# BlueNRG2 register map
Vendor: STMicroelectronics; Series: BlueNRG1; File version: 1.0.0
ARM 32-bit Cortex-M0 Microcontroller based device, CPU clock up to 32MHz
CPU: CM0 r0p0, little endian, no MPU, no FPU, 2 interrupt priority bits
Registers are 32-bit, read-write, reset 0x0 unless marked. A register's access mark holds for its fields unless they carry their own. Offsets are from the block's base; lines under a group give offsets from that group; [hi:lo] are bit positions; {n}, {i} and the like mark numbered series; 'fields as' and 'values as' point back to an identical list; <NAME> marks a mode.

## Memory map
0x40000000 GPIO size 0x1000 — GPIO Controller
0x40100000 FLASH size 0x1000 — Flash Controller
0x40200000 SYSTEM_CTRL size 0x1000 — System controller
0x40300000 UART size 0x1000
0x40400000 SPI size 0x1000 — Serial peripheral interface
0x40700000 WDG size 0x1000 — Watchdog
0x40800000 ADC size 0x1000
0x40900000 CKGEN_SOC size 0x1000 — Clock Gen SOC
0x40A00000 I2C2 size 0x1000
0x40B00000 I2C1 size 0x1000
0x40C00000 AHBUPCONV size 0x1000 — AHB up/down converter converter
0x40D00000 MFT1 size 0x1000
0x40E00000 MFT2 size 0x1000
0x40F00000 RTC size 0x1000 — Real-Time Counter
0x48000000 BLUE_CTRL size 0x1000 — BLUE Controller
0x48100000 CKGEN_BLE size 0x1000 — Clock Gen BLE
0xA0000000 DMA size 0x1000
0xA0000008 DMA_CH0 size 0x1000 — DMA channel
0xA000001C DMA_CH1 size 0x1000
0xA0000030 DMA_CH2 size 0x1000
0xA0000044 DMA_CH3 size 0x1000
0xA0000058 DMA_CH4 size 0x1000
0xA000006C DMA_CH5 size 0x1000
0xA0000080 DMA_CH6 size 0x1000
0xA0000094 DMA_CH7 size 0x1000
0xB0000000 RNG size 0x1000
0xC0000000 PKA size 0x1000

## Interrupts
0 GPIO — GPIO bus interrupt
1 NVM (FLASH) — Non-volatile memory (Flash) controller interrupt
4 UART — UART interrupt
5 SPI — SPI interrupt
6 BLUE_CTRL — BLUE controller interrupt
7 WDG — Watchdog interrupt
13 ADC — ADC interrupt
14 I2C2 — I2C 2 interrupt
15 I2C1 — I2C 1 interrupt
17 MFT1A (MFT1) — Multi functional timer MFT1 interrupt A
18 MFT1B (MFT1) — Multi functional timer MFT1 interrupt B
19 MFT2A (MFT2) — Multi functional timer MFT2 interrupt A
20 MFT2B (MFT2) — Multi functional timer MFT2 interrupt B
21 RTC — RTC interrupt
22 PKA — PKA interrupt
23 DMA — DMA interrupt

## GPIO — GPIO Controller
Base 0x40000000
0x00 DATA (reset mask 0x3FFFFFF) — IO0 to IO14 data value.<p>Writing to a bit will drive the written value on the corresponding IO when it is configured in GPIO mode and the output direction. Reading a bit indicates the pin value</p>
0x04 OEN (reset mask 0x3FFFFFF) — GPIO output enable register (1 bit per GPIO).<ul><li>0: input mode.</li><li>1: output mode</li></ul>
0x08 PE reset 0x3FFFFFF (reset mask 0x3FFFFFF) — Pull enable (1 bit per IO).<ul><li>0: pull disabled.</li><li>1: pull enabled</li></ul>
0x0C DS (reset mask 0x3FFFFFF) — IO driver strength (1 bit per IO).<ul><li>0: 2mA.</li><li>1: 4 mA</li></ul>
0x10 IS (reset mask 0x3FFFFFF) — Interrupt sense register (1 bit per IO).<ul><li>0: edge detection.</li><li>1: level detection</li></ul>
0x14 IBE (reset mask 0x3FFFFFF) — Interrupt edge register (1 bit per IO).<ul><li>0: single edge.</li><li>1: both edges</li></ul>
0x18 IEV (reset mask 0x3FFFFFF) — Interrupt event register (1 bit per IO).<ul><li>0: falling edge or low level.</li><li>1: rising edge or high level</li></ul>
0x1C IE (reset mask 0x3FFFFFF) — Interrupt mask register (1 bit per IO).<ul><li>0: interrupt disabled.</li><li>1: interrupt enabled.</li></ul>
0x24 MIS ro (reset mask 0x3FFFFFF) — Masked interrupt status register (1 bit per IO)
0x28 IC wo (reset mask 0x3FFFFFF) write-1-clears — Interrupt clear register (1 bit per IO).<ul><li>0: no effect.</li><li>1: clear interrupt</li></ul>
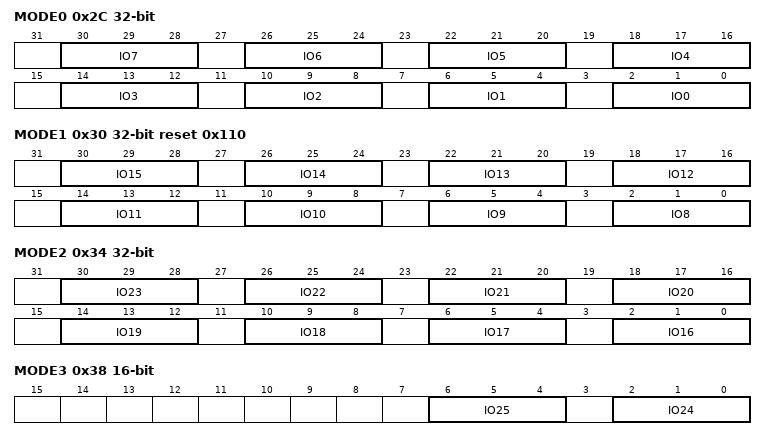
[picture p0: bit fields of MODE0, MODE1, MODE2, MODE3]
0x2C MODE0 — Select mode for IO0 to IO7.<ul><li>000b: GPIO mode.</li><li>001b: Serial1 mode.</li><li>100b: Serial0 mode.</li><li>101b: Microphone/ADC mode.</li></ul>
  [all] fields
    0=GPIO_MODE; 1=SERIAL1_MODE; 2=STANDALONE_MODE; 3=BLUE_MODE (BLE mode); 4=SERIAL0_MODE; 5=MICROPHONE_ADC_MODE (ADC mode for microphone)
  [4n+2:4n] IO{n} (n=0..7) — IO{n} mode
0x30 MODE1 reset 0x110 — Select mode for IO8 to IO15.<ul><li>000b: GPIO mode.</li><li>001b: Serial1 mode.</li><li>100b: Serial0 mode.</li><li>101b: Microphone/ADC mode.</li></ul>
  [all] fields
    values as the fields of MODE0
  [4n-30:4n-32] IO{n} (n=8..15) — IO{n} mode
0x34 MODE2 — Select mode for IO16 to IO23
  [all] fields
    values as the fields of MODE0
  [4n-62:4n-64] IO{n} (n=16..23) — IO{n} mode
0x38 MODE3 16-bit — Select mode for IO24 to IO25
  [6:4] IO25 — IO25 mode
    values as the fields of MODE0
  [2:0] IO24 — IO24 mode
    values as the fields of MODE0
0x3C DATS (reset mask 0x3FFFFFF) — Set some bits of DATA when in GPIO mode without affecting the others (1 bit per IO).<ul><li>0: no effect.</li><li>1: set at 1 the bit</li></ul>
0x40 DATC (reset mask 0x3FFFFFF) — Clear some bits of DATA when in GPIO mode without affecting the others (1 bit per IO).<ul><li>0: no effect.</li><li>1: clear at 0 the bit</li></ul>
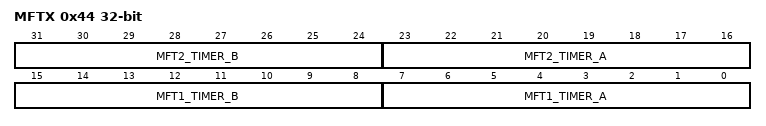
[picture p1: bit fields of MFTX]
0x44 MFTX — Select the IO to be used as capture input for the MFTX timers
  [all] fields
    {v}=IO{v} (v=0..25)
  [31:24] MFT2_TIMER_B — MFT2 timer B.<ul><li>0x00: IO0.</li><li>0x01: IO1</li><li>0x02: IO2</li><li>...</li><li>0x0E: IO14</li></ul>
  [23:16] MFT2_TIMER_A — MFT2 timer A.<ul><li>0x00: IO0.</li><li>0x01: IO1</li><li>0x02: IO2</li><li>...</li><li>0x0E: IO14</li></ul>
  [15:8] MFT1_TIMER_B — MFT1 timer B.<ul><li>0x00: IO0.</li><li>0x01: IO1</li><li>0x02: IO2</li><li>...</li><li>0x0E: IO14</li></ul>
  [7:0] MFT1_TIMER_A — MFT1 timer A.<ul><li>0x00: IO0.</li><li>0x01: IO1</li><li>0x02: IO2</li><li>...</li><li>0x0E: IO14</li></ul>

## Licence text in the file
License
